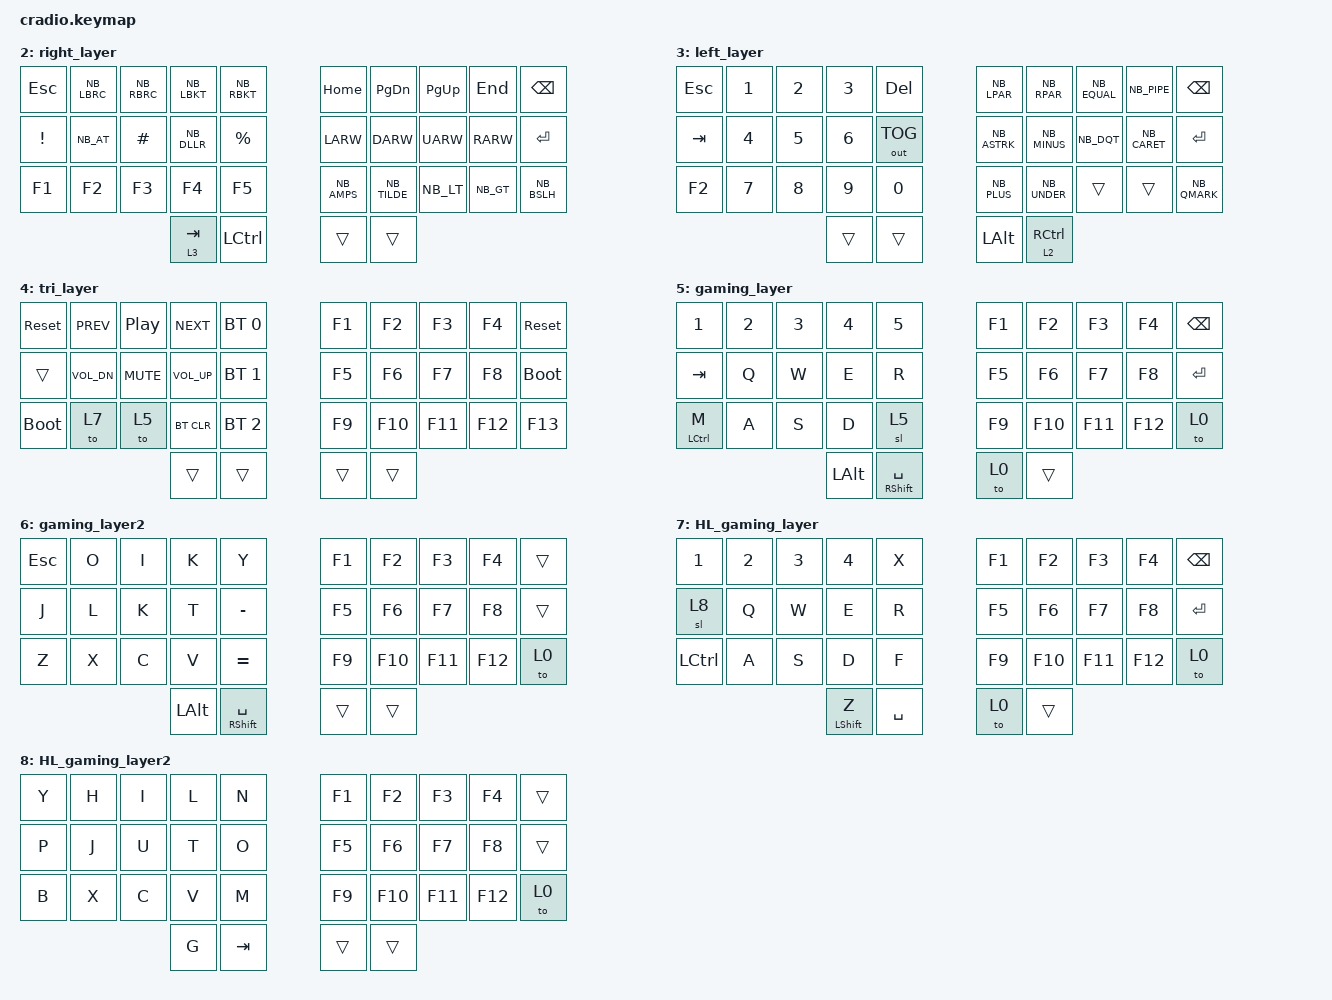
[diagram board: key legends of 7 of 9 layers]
// Copyright (c) 2022 The ZMK Contributors
// SPDX-License-Identifier: MIT

#include <behaviors.dtsi>
#include <dt-bindings/zmk/keys.h>
#include <dt-bindings/zmk/bt.h>
#include <dt-bindings/zmk/outputs.h>
#include "keys_nb.h"
#include <dt-bindings/zmk/pointing.h>

// Home row mods macro
#define HRML(k1,k2,k3,k4) &ht LSHFT k1  &ht LALT k2  &ht LCTRL k3  &ht LGUI k4
#define HRMR(k1,k2,k3,k4) &ht RGUI k1  &ht RCTRL k2  &ht LALT k3  &ht RSHFT k4

/ {
    combos {
        compatible = "zmk,combos";
        combo_Layer0 {
            timeout-ms = <50>;
            key-positions = <4 5>;
            bindings = <&to 0>;
        };
        combo_Layer1 {
            timeout-ms = <50>;
            key-positions = <3 6>;
            bindings = <&to 1>;
        };
        combo_BOOTLOADER {
            timeout-ms = <50>;
            key-positions = <0 9>;
            bindings = <&bootloader>;
        };
        combo_RCLK {
            timeout-ms = <50>;
            key-positions = <17 18>;
            bindings = <&mkp MB2>;
        };
        combo_esc {
            timeout-ms = <50>;
            key-positions = <0 1>;
            bindings = <&kp ESC>;
        };
        combo_bspc {
            timeout-ms = <50>;
            key-positions = <8 9>;
            bindings = <&kp BSPC>;
        };
        combo_delete {
            timeout-ms = <50>;
            key-positions = <3 4>;
            bindings = <&kp DEL>;
        };
        combo_enter {
            timeout-ms = <50>;
            key-positions = <18 19>;
            bindings = <&kp ENTER>;
        };
        combo_print-screen {
            timeout-ms = <50>;
            key-positions = <0 4>;
            bindings = <&kp PSCRN>;
        };
        combo_aa {
            timeout-ms = <50>;
            key-positions = <10 11>;
            bindings = <&kp LBKT>;
        };
        combo_ae {
            timeout-ms = <50>;
            key-positions = <2 10>;
            bindings = <&kp SQT>;
        };
        combo_oe {
            timeout-ms = <50>;
            key-positions = <2 8>;
            bindings = <&kp SEMI>;
        };
        combo_qmark {
            timeout-ms = <50>;
            key-positions = <28 29>;
            bindings = <&kp NB_QMARK>;
        };
        combo_prev {
            timeout-ms = <50>;
            key-positions = <1 2>;
            bindings = <&kp C_PREV>;
        };
        combo_play-pause {
            timeout-ms = <50>;
            key-positions = <2 3>;
            bindings = <&kp C_PP>;
        };
        combo_next {
            timeout-ms = <50>;
            key-positions = <2 4>;
            bindings = <&kp C_NEXT>;
        };
        combo_vol-dn {
            timeout-ms = <50>;
            key-positions = <11 12>;
            bindings = <&kp C_VOL_DN>;
        };
        combo_mute {
            timeout-ms = <50>;
            key-positions = <12 13>;
            bindings = <&kp C_MUTE>;
        };
        combo_vol-up {
            timeout-ms = <50>;
            key-positions = <12 14>;
            bindings = <&kp C_VOL_UP>;
        };
        combo_cut {
            timeout-ms = <50>;
            key-positions = <20 21>;
            bindings = <&kp LC(X)>;
        };
        combo_copy {
            timeout-ms = <50>;
            key-positions = <21 22>;
            bindings = <&kp LC(C)>;
        };
        combo_paste {
            timeout-ms = <50>;
            key-positions = <22 23>;
            bindings = <&kp LC(V)>;
        };
    };
};

/ {
    behaviors {
        ht: hold_tap {
            label = "hold_tap";
            compatible = "zmk,behavior-hold-tap";
            #binding-cells = <2>;
            flavor = "tap-preferred";
            tapping-term-ms = <220>;
            quick-tap-ms = <150>;
            global-quick-tap;
            bindings = <&kp>, <&kp>;
        };
        td: tapdance {
            compatible = "zmk,behavior-hold-tap";
            label = "TAPDANCE";
            #binding-cells = <2>;
            tapping-term-ms = <150>;
            quick_tap_ms = <0>;
            flavor = "tap-preferred";
            bindings = <&kp>, <&kp>;
        };
    };

    conditional_layers {
        compatible = "zmk,conditional-layers";
        tri_layer {
            if-layers = <2 3>;
            then-layer = <4>;
        };
    };

    keymap {
        compatible = "zmk,keymap";
        default_layer {
            bindings = <
        //╭──────────┬──────────┬──────────┬──────────┬──────────╮   ╭──────────┬──────────┬──────────┬──────────┬──────────╮
        //│  Q       │  W       │  E       │  R       │  T       │   │  Y       │  U       │  I       │  O       │  P       │
            &kp Q      &kp W      &kp E      &kp R      &kp T          &kp Y      &kp U      &kp I      &kp O      &kp P
        //├──────────┼──────────┼──────────┼──────────┼──────────┤   ├──────────┼──────────┼──────────┼──────────┼──────────┤
        //│  A       │  S       │  D       │  F       │  G       │   │  H       │  J       │  K       │  L       │ ' "      │
            HRML(A,        S,         D,         F)     &kp G          &kp H      HRMR(J,        K,         L,     NB_SQT)
        //├──────────┼──────────┼──────────┼──────────┼──────────┤   ├──────────┼──────────┼──────────┼──────────┼──────────┤
        //│  Z       │  X       │  C       │  V       │  B       │   │  N       │  M       │ , <      │ . >      │ / ?      │
            &kp Z      &kp X      &kp C      &kp V      &kp B          &kp N      &kp M      &kp COMMA  &kp DOT   &kp NB_FSLH
        //╰──────────┴──────────┴──────────┼──────────┼──────────┤   ├──────────┼──────────┼──────────┴──────────┴──────────╯
                                         &lt 3 TAB  &td LCTRL ENTER &td RSHFT SPACE  &lt 2 BSPC
        //                                 ╰──────────┴──────────╯   ╰──────────┴──────────╯
            >;
        };

        colemak_layer { //Layer 1
            bindings = <
        //╭──────────┬──────────┬──────────┬──────────┬──────────╮   ╭──────────┬──────────┬──────────┬──────────┬──────────╮
        //│  Q       │  W       │  F       │  P       │  B       │   │  J       │  L       │  U       │  Y       │  ' "     │
            &kp Q      &kp W      &kp F      &kp P      &kp B          &kp J      &kp L      &kp U      &kp Y      &kp SQT
        //├──────────┼──────────┼──────────┼──────────┼──────────┤   ├──────────┼──────────┼──────────┼──────────┼──────────┤
        //│  A       │  R       │  S       │  T       │  G       │   │  M       │  N       │  E       │  I       │  O       │
            HRML(A,        R,         S,         T)     &kp G          &kp M      HRMR(N,        E,         I,        O)
        //├──────────┼──────────┼──────────┼──────────┼──────────┤   ├──────────┼──────────┼──────────┼──────────┼──────────┤
        //│  Z       │  X       │  C       │  D       │  V       │   │  K       │  H       │ , <      │ . >      │ / ?      │
            &kp Z      &kp X      &kp C      &kp D      &kp V          &kp K      &kp H      &kp COMMA  &kp DOT    &kp FSLH
        //╰──────────┴──────────┴──────────┼──────────┼──────────┤   ├──────────┼──────────┼──────────┴──────────┴──────────╯
                                         &lt 3 TAB  &td LCTRL ENTER &td RSHFT SPACE  &lt 2 BSPC
        //                                 ╰──────────┴──────────╯   ╰──────────┴──────────╯
            >;
        };

        right_layer { // Layer 2
            bindings = <
        //╭──────────┬──────────┬──────────┬──────────┬──────────╮   ╭──────────┬──────────┬──────────┬──────────┬──────────╮
        //│ ESC      │  {       │  }       │  [       │  ]       │   │ HOME     │ PAGE DN  │ PAGE UP  │ END      │  BSPC    │
            &kp ESC &kp NB_LBRC &kp NB_RBRC &kp NB_LBKT &kp NB_RBKT    &kp HOME   &kp PG_DN  &kp PG_UP  &kp END    &kp BSPC 
        //├──────────┼──────────┼──────────┼──────────┼──────────┤   ├──────────┼──────────┼──────────┼──────────┼──────────┤
        //│  !       │  @       │  #       │  $       │  %       │   │ LEFT     │ DOWN     │ UP       │ RIGHT    │  ENTER   │
            &kp EXCL   &kp NB_AT  &kp HASH  &kp NB_DLLR &kp PRCNT      &kp LARW   &kp DARW   &kp UARW   &kp RARW   &kp ENTER
        //├──────────┼──────────┼──────────┼──────────┼──────────┤   ├──────────┼──────────┼──────────┼──────────┼──────────┤
        //│          │          │          │          │          │   │  &       │  ~       │  <       │  >       │  \       │
            &kp F1     &kp F2     &kp F3     &kp F4     &kp F5       &kp NB_AMPS &kp NB_TILDE &kp NB_LT &kp NB_GT &kp NB_BSLH
        //╰──────────┴──────────┴──────────┼──────────┼──────────┤   ├──────────┼──────────┼──────────┴──────────┴──────────╯
                                             &lt 3 TAB  &kp LCTRL      &trans     &trans
        //                                 ╰──────────┴──────────╯   ╰──────────┴──────────╯
            >;
        };

        left_layer { // Layer 3
            bindings = <
        //╭──────────┬──────────┬──────────┬──────────┬──────────╮   ╭──────────┬──────────┬──────────┬──────────┬──────────╮
        //│ ESC      │  1       │  2       │  3       │ DELETE   │   │  (       │  )       │  =       │  |       │  BSPC    │
            &kp ESC    &kp N1     &kp N2     &kp N3     &kp DEL    &kp NB_LPAR &kp NB_RPAR &kp NB_EQUAL &kp NB_PIPE &kp BSPC 
        //├──────────┼──────────┼──────────┼──────────┼──────────┤   ├──────────┼──────────┼──────────┼──────────┼──────────┤
        //│ TAB      │  4       │  5       │  6       │ USB/BLE  │   │  *       │  -       │  "       │  ^       │ ENTER    │
            &kp TAB    &kp N4     &kp N5     &kp N6  &out OUT_TOG &kp NB_ASTRK &kp NB_MINUS &kp NB_DQT  &kp NB_CARET &kp ENTER
        //├──────────┼──────────┼──────────┼──────────┼──────────┤   ├──────────┼──────────┼──────────┼──────────┼──────────┤
        //│          │  7       │  8       │  9       │  0       │   │  +       │  _       │          │          │  ?       │
            &kp F2     &kp N7     &kp N8     &kp N9     &kp N0     &kp NB_PLUS &kp NB_UNDER  &trans     &trans    &kp NB_QMARK
        //╰──────────┴──────────┴──────────┼──────────┼──────────┤   ├──────────┼──────────┼──────────┴──────────┴──────────╯
                                             &trans     &trans         &kp LALT   &lt 2 RCTRL
        //                                 ╰──────────┴──────────╯   ╰──────────┴──────────╯
            >;
        };

        tri_layer { // Layer 4
            bindings = <
        //╭──────────┬──────────┬──────────┬──────────┬──────────╮   ╭──────────┬──────────┬──────────┬──────────┬──────────╮
        //│ RESET    │          │          │          │PROFILE 0 │   │          │          │          │          │  RESET   │
           &sys_reset &kp C_PREV &kp C_PP   &kp C_NEXT &bt BT_SEL 0    &kp F1     &kp F2     &kp F3     &kp F4    &sys_reset
        //├──────────┼──────────┼──────────┼──────────┼──────────┤   ├──────────┼──────────┼──────────┼──────────┼──────────┤
        //│          │          │          │          │PROFILE 1 │   │          │          │          │          │BOOTLOADER│
            &trans   &kp C_VOL_DN &kp C_MUTE &kp C_VOL_UP &bt BT_SEL 1 &kp F5    &kp F6     &kp F7     &kp F8    &bootloader
        //├──────────┼──────────┼──────────┼──────────┼──────────┤   ├──────────┼──────────┼──────────┼──────────┼──────────┤
        //│BOOTLOADER│          │          │ CLEAR BT │PROFILE 2 │   │          │          │          │          │          │
          &bootloader   &to 7      &to 5    &bt BT_CLR &bt BT_SEL 2    &kp F9     &kp F10    &kp F11    &kp F12    &kp F13
        //╰──────────┴──────────┴──────────┼──────────┼──────────┤   ├──────────┼──────────┼──────────┴──────────┴──────────╯
                                             &trans     &trans         &trans     &trans
        //                                 ╰──────────┴──────────╯   ╰──────────┴──────────╯
            >;
        };
        gaming_layer { // Layer 5
            bindings = <
        //╭──────────┬──────────┬──────────┬──────────┬──────────╮   ╭──────────┬──────────┬──────────┬──────────┬──────────╮
        //│    1     │    2     │    3     │    4     │    5     │   │          │          │          │          │          │
            &kp N1     &kp N2     &kp N3     &kp N4     &kp N5         &kp F1     &kp F2     &kp F3     &kp F4     &kp BSPC  
        //├──────────┼──────────┼──────────┼──────────┼──────────┤   ├──────────┼──────────┼──────────┼──────────┼──────────┤
        //│  TAB     │    Q     │    W     │    E     │    R     │   │          │          │          │          │          │
           &kp TAB     &kp Q      &kp W      &kp E      &kp R          &kp F5     &kp F6     &kp F7     &kp F8     &kp ENTER 
        //├──────────┼──────────┼──────────┼──────────┼──────────┤   ├──────────┼──────────┼──────────┼──────────┼──────────┤
        //│  CTRL/M  │    A     │    S     │    D     │ Layer G2 │   │          │          │          │          │          │
         &td LCTRL M   &kp A      &kp S      &kp D      &sl 5          &kp F9     &kp F10    &kp F11    &kp F12    &to 0
        //╰──────────┴──────────┴──────────┼──────────┼──────────┤   ├──────────┼──────────┼──────────┴──────────┴──────────╯
                                            &kp LALT  &td RSHFT SPACE  &to 0      &trans
        //                                 ╰──────────┴──────────╯   ╰──────────┴──────────╯
            >;
        };
        gaming_layer2 { // Layer 6
            bindings = <
        //╭──────────┬──────────┬──────────┬──────────┬──────────╮   ╭──────────┬──────────┬──────────┬──────────┬──────────╮
        //│  ESC     │    O     │    I     │    U     │    Y     │   │          │          │          │          │          │
            &kp ESC    &kp O      &kp I      &kp K      &kp Y          &kp F1     &kp F2     &kp F3     &kp F4     &trans    
        //├──────────┼──────────┼──────────┼──────────┼──────────┤   ├──────────┼──────────┼──────────┼──────────┼──────────┤
        //│  J       │    L     │    K     │    T     │    -     │   │          │          │          │          │          │
           &kp J       &kp L      &kp K      &kp T      &kp MINUS      &kp F5     &kp F6     &kp F7     &kp F8     &trans     
        //├──────────┼──────────┼──────────┼──────────┼──────────┤   ├──────────┼──────────┼──────────┼──────────┼──────────┤
        //│  Z       │    X     │    C     │    V     │   =      │   │          │          │          │          │          │
           &kp Z       &kp X      &kp C      &kp V      &kp EQUAL      &kp F9     &kp F10    &kp F11    &kp F12    &to 0
        //╰──────────┴──────────┴──────────┼──────────┼──────────┤   ├──────────┼──────────┼──────────┴──────────┴──────────╯
                                            &kp LALT  &td RSHFT SPACE  &trans     &trans
        //                                 ╰──────────┴──────────╯   ╰──────────┴──────────╯
            >;
        };
        HL_gaming_layer { // Layer 7
            bindings = <
        //╭──────────┬──────────┬──────────┬──────────┬──────────╮   ╭──────────┬──────────┬──────────┬──────────┬──────────╮
        //│    1     │    2     │    3     │    4     │    X     │   │          │          │          │          │          │
            &kp N1     &kp N2     &kp N3     &kp N4     &kp X          &kp F1     &kp F2     &kp F3     &kp F4     &kp BSPC  
        //├──────────┼──────────┼──────────┼──────────┼──────────┤   ├──────────┼──────────┼──────────┼──────────┼──────────┤
        //│ HL_2     │    Q     │    W     │    E     │    R     │   │          │          │          │          │          │
           &sl 8       &kp Q      &kp W      &kp E      &kp R          &kp F5     &kp F6     &kp F7     &kp F8     &kp ENTER 
        //├──────────┼──────────┼──────────┼──────────┼──────────┤   ├──────────┼──────────┼──────────┼──────────┼──────────┤
        //│  CTRL    │    A     │    S     │    D     │    F     │   │          │          │          │          │          │
           &kp LCTRL  &kp A      &kp S      &kp D       &kp F          &kp F9     &kp F10    &kp F11    &kp F12    &to 0
        //╰──────────┴──────────┴──────────┼──────────┼──────────┤   ├──────────┼──────────┼──────────┴──────────┴──────────╯
                                         &td LSHFT Z    &kp SPACE      &to 0      &trans
        //                                 ╰──────────┴──────────╯   ╰──────────┴──────────╯
            >;
        };
        HL_gaming_layer2 { // Layer 8
            bindings = <
        //╭──────────┬──────────┬──────────┬──────────┬──────────╮   ╭──────────┬──────────┬──────────┬──────────┬──────────╮
        //│    Y     │    H     │    I     │    L     │    N     │   │          │          │          │          │          │
            &kp Y      &kp H      &kp I      &kp L      &kp N          &kp F1     &kp F2     &kp F3     &kp F4     &trans    
        //├──────────┼──────────┼──────────┼──────────┼──────────┤   ├──────────┼──────────┼──────────┼──────────┼──────────┤
        //│   P      │   J      │    U     │    T     │    O     │   │          │          │          │          │          │
           &kp P      &kp J      &kp U      &kp T       &kp O          &kp F5     &kp F6     &kp F7     &kp F8     &trans     
        //├──────────┼──────────┼──────────┼──────────┼──────────┤   ├──────────┼──────────┼──────────┼──────────┼──────────┤
        //│  B       │    X     │    C     │    V     │   M      │   │          │          │          │          │          │
           &kp B       &kp X      &kp C      &kp V      &kp M          &kp F9     &kp F10    &kp F11    &kp F12    &to 0
        //╰──────────┴──────────┴──────────┼──────────┼──────────┤   ├──────────┼──────────┼──────────┴──────────┴──────────╯
                                            &kp G       &kp TAB        &trans     &trans
        //                                 ╰──────────┴──────────╯   ╰──────────┴──────────╯
            >;
        };
    };
};
